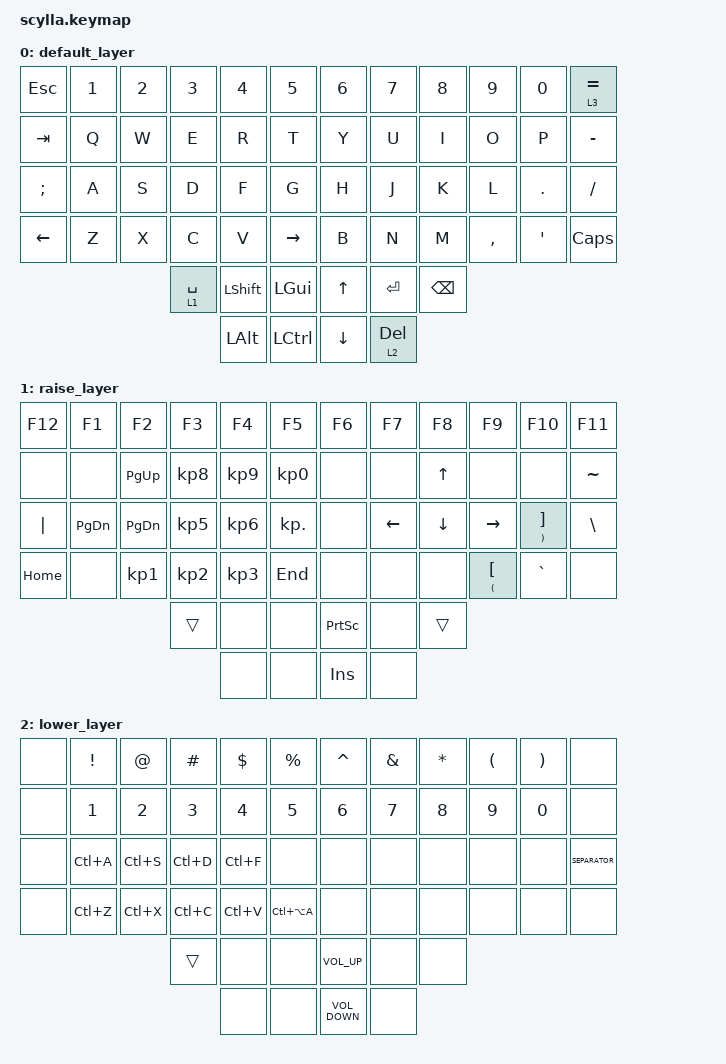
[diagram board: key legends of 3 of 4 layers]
#include <behaviors.dtsi>
#include <dt-bindings/zmk/bt.h>
#include <dt-bindings/zmk/keys.h>

#define DEFAULT 0
#define LWR 1
#define RSE 2
#define ADJ 3

/ {
    combos { compatible = "zmk,combos"; };

    behaviors {
        ltq: ltq {
            compatible = "zmk,behavior-hold-tap";
            label = "LTQ";
            bindings = <&mo>, <&kp>;

            #binding-cells = <2>;
            tapping-term-ms = <200>;
            quick-tap-ms = <180>;
            global-quick-tap;
        };
    };

    keymap {
        compatible = "zmk,keymap";

        default_layer {
            bindings = <
&kp ESC         &kp NUMBER_1  &kp NUMBER_2  &kp NUMBER_3  &kp NUMBER_4    &kp NUMBER_5       &kp NUMBER_6    &kp NUMBER_7  &kp NUMBER_8   &kp NUMBER_9  &kp NUMBER_0      &lt 3 EQUAL
&kp TAB         &kp Q         &kp W         &kp E         &kp R           &kp T              &kp Y           &kp U         &kp I          &kp O         &kp P             &kp MINUS
&kp SEMICOLON   &kp A         &kp S         &kp D         &kp F           &kp G              &kp H           &kp J         &kp K          &kp L         &kp PERIOD        &kp SLASH
&kp LEFT_ARROW  &kp Z         &kp X         &kp C         &kp V           &kp RIGHT_ARROW    &kp B           &kp N         &kp M          &kp COMMA     &kp SINGLE_QUOTE  &kp CAPSLOCK
                                            &lt 1 SPACE   &kp LEFT_SHIFT  &kp LEFT_GUI       &kp UP_ARROW    &kp RETURN    &kp BACKSPACE
                                                          &kp LEFT_ALT    &kp LCTRL          &kp DOWN_ARROW  &lt 2 DELETE
            >;
        };

        raise_layer {
            bindings = <
&kp F12   &kp F1         &kp F2           &kp F3           &kp F4           &kp F5             &kp F6           &kp F7    &kp F8    &kp F9                             &kp F10                              &kp F11
&none     &none          &kp PAGE_UP      &kp KP_NUMBER_8  &kp KP_NUMBER_9  &kp KP_NUMBER_0    &none            &none     &kp UP    &none                              &none                                &kp TILDE
&kp PIPE  &kp PAGE_DOWN  &kp PAGE_DOWN    &kp KP_NUMBER_5  &kp KP_NUMBER_6  &kp KP_DOT         &none            &kp LEFT  &kp DOWN  &kp RIGHT                          &mt RIGHT_PARENTHESIS RIGHT_BRACKET  &kp BACKSLASH
&kp HOME  &none          &kp KP_NUMBER_1  &kp KP_NUMBER_2  &kp KP_NUMBER_3  &kp END            &none            &none     &none     &mt LEFT_PARENTHESIS LEFT_BRACKET  &kp GRAVE                            &none
                                          &trans           &none            &none              &kp PRINTSCREEN  &none     &trans
                                                           &none            &none              &kp INS          &none
            >;
        };

        lower_layer {
            bindings = <
&none  &kp EXCL      &kp AT        &kp HASH      &kp DLLR      &kp PRCNT        &kp CARET          &kp AMPS      &kp ASTRK     &kp LPAR      &kp RPAR      &none
&none  &kp NUMBER_1  &kp NUMBER_2  &kp NUMBER_3  &kp NUMBER_4  &kp NUMBER_5     &kp NUMBER_6       &kp NUMBER_7  &kp NUMBER_8  &kp NUMBER_9  &kp NUMBER_0  &none
&none  &kp LC(A)     &kp LC(S)     &kp LC(D)     &kp LC(F)     &none            &none              &none         &none         &none         &none         &kp SEPARATOR
&none  &kp LC(Z)     &kp LC(X)     &kp LC(C)     &kp LC(V)     &kp LC(LA(A))    &none              &none         &none         &none         &none         &none
                                   &trans        &none         &none            &kp C_VOLUME_UP    &none         &none
                                                 &none         &none            &kp C_VOLUME_DOWN  &none
            >;
        };

        adjust_layer {
            bindings = <
&bt BT_CLR  &bt BT_SEL 0  &bt BT_SEL 1  &bt BT_SEL 2  &bt BT_SEL 3  &bt BT_SEL 4    &none  &none  &none  &none  &none  &none
&none       &none         &none         &none         &none         &none           &none  &none  &none  &none  &none  &none
&none       &none         &none         &none         &none         &none           &none  &none  &none  &none  &none  &bt BT_CLR
&none       &none         &none         &none         &bootloader   &none           &none  &none  &none  &none  &none  &none
                                        &none         &none         &none           &none  &none  &none
                                                      &none         &none           &none
            >;
        };
    };
};
